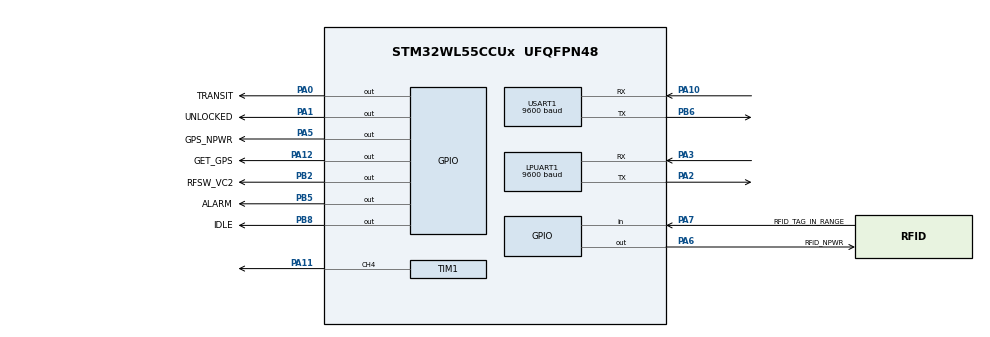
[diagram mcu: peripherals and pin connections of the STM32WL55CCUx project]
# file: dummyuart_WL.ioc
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ADC.ClockPrescaler=ADC_CLOCK_SYNC_PCLK_DIV4
ADC.NbrOfConversion=1
ADC.Overrun=ADC_OVR_DATA_OVERWRITTEN
ADC.SelectedChannel=ADC_CHANNEL_TEMPSENSOR|ADC_CHANNEL_VREFINT
LPUART1.BaudRate=9600
LPUART1.SwapParam=UART_ADVFEATURE_SWAP_ENABLE
Mcu.Family=STM32WL
Mcu.Name=STM32WL55CCUx
Mcu.Package=UFQFPN48
NVIC.LPUART1_IRQn=true\:0\:0\:false\:false\:true\:true\:true\:true
NVIC.PriorityGroup=NVIC_PRIORITYGROUP_4
NVIC.USART1_IRQn=true\:0\:0\:false\:false\:true\:true\:true\:true
PA0.GPIO_Label=TRANSIT
PA0.PinState=GPIO_PIN_SET
PA0.Signal=GPIO_Output
PA1.GPIO_Label=UNLOCKED
PA1.PinState=GPIO_PIN_SET
PA1.Signal=GPIO_Output
PA10.Mode=Asynchronous
PA10.Signal=USART1_RX
PA11.GPIO_Speed=GPIO_SPEED_FREQ_HIGH
PA11.Signal=S_TIM1_CH4
PA12.GPIO_Label=GET_GPS
PA12.PinState=GPIO_PIN_SET
PA12.Signal=GPIO_Output
PA13.Mode=Serial_Wire
PA13.Signal=DEBUG_JTMS-SWDIO
PA14.Mode=Serial_Wire
PA14.Signal=DEBUG_JTCK-SWCLK
PA2.Mode=Asynchronous
PA2.Signal=LPUART1_TX
PA3.Mode=Asynchronous
PA3.Signal=LPUART1_RX
PA5.GPIO_Label=GPS_NPWR
PA5.Signal=GPIO_Output
PA6.GPIO_Label=RFiD_NPWR
PA6.Signal=GPIO_Output
PA7.GPIO_Label=RFID_TAG_IN_RANGE
PA7.Signal=GPIO_Input
PB2.GPIO_Label=RFSW_VC2
PB2.Signal=GPIO_Output
PB4.Signal=DEBUG_JTRST
PB5.GPIO_Label=ALARM
PB5.PinState=GPIO_PIN_SET
PB5.Signal=GPIO_Output
PB6.Mode=Asynchronous
PB6.Signal=USART1_TX
PB8.GPIO_Label=IDLE
PB8.PinState=GPIO_PIN_SET
PB8.Signal=GPIO_Output
ProjectManager.HeapSize=0x200
ProjectManager.StackSize=0x400
ProjectManager.TargetToolchain=Makefile
RCC.AHBFreq_Value=48000000
RCC.APB1Freq_Value=48000000
RCC.APB1TimFreq_Value=48000000
RCC.APB2Freq_Value=48000000
RCC.APB2TimFreq_Value=48000000
RCC.APB3Freq_Value=48000000
RCC.CortexFreq_Value=48000000
RCC.HCLKFreq_Value=48000000
RCC.HSE_VALUE=8000000
RCC.HSI_VALUE=16000000
RCC.LPUART1CLockSelection=RCC_LPUART1CLKSOURCE_HSI
RCC.LSE_VALUE=32768
RCC.MSIClockRange=RCC_MSIRANGE_11
RCC.SYSCLKFreq_VALUE=48000000
RCC.USART1CLockSelection=RCC_USART1CLKSOURCE_HSI
RCC.VCOOutputFreq_Value=384000000
SH.S_TIM1_CH4.0=TIM1_CH4,PWM Generation4 CH4
TIM1.AutoReloadPreload=TIM_AUTORELOAD_PRELOAD_DISABLE
TIM1.Channel-PWM\ Generation4\ CH4=TIM_CHANNEL_4
TIM1.OCFastMode_PWM-PWM\ Generation4\ CH4=TIM_OCFAST_ENABLE
TIM1.Period=3
TIM1.Prescaler=2400
TIM1.Pulse-PWM\ Generation4\ CH4=2
TIM2.Period=5000000
TIM2.Prescaler=48000-1
USART1.AutoBaudRateEnableParam=UART_ADVFEATURE_AUTOBAUDRATE_DISABLE
USART1.BaudRate=9600
USART1.DataInvertParam=ADVFEATURE_DATAINV_DISABLE
USART1.FIFOMode=FIFOMODE_ENABLE
USART1.OneBitSampling=UART_ONE_BIT_SAMPLE_ENABLE
USART1.OverSampling=UART_OVERSAMPLING_8
USART1.RxPinLevelInvertParam=ADVFEATURE_RXINV_DISABLE
USART1.SwapParam=ADVFEATURE_SWAP_ENABLE
USART1.TxPinLevelInvertParam=ADVFEATURE_TXINV_DISABLE
USART1.VirtualMode-Asynchronous=VM_ASYNC
USART1.WordLength=WORDLENGTH_8B
VP_ADC_TempSens_Input.Mode=IN-TempSens
VP_ADC_Vref_Input.Mode=IN-Vrefint
VP_TIM1_VS_ClockSourceINT.Mode=Internal
VP_TIM2_VS_ClockSourceINT.Mode=Internal
board=custom

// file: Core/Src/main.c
/* USER CODE BEGIN Header */
/**
  ******************************************************************************
  * @file           : main.c
  * @brief          : Main program body
  ******************************************************************************
  * @attention
  *
  * Copyright (c) 2022 STMicroelectronics.
  * All rights reserved.
  *
  * This software is licensed under terms that can be found in the LICENSE file
  * in the root directory of this software component.
  * If no LICENSE file comes with this software, it is provided AS-IS.
  *
  ******************************************************************************
  */
/* USER CODE END Header */
#include "main.h"

 ADC_HandleTypeDef hadc;

UART_HandleTypeDef hlpuart1;
UART_HandleTypeDef huart1;

TIM_HandleTypeDef htim1;
TIM_HandleTypeDef htim2;

void SystemClock_Config(void);
static void MX_GPIO_Init(void);
static void MX_USART1_UART_Init(void);
static void MX_ADC_Init(void);
static void MX_LPUART1_UART_Init(void);
static void MX_TIM1_Init(void);
static void MX_TIM2_Init(void);

/* USER CODE BEGIN 0 */
char dummymsg[]={
		 "dummymessage \n\r"
 };
/* USER CODE END 0 */

int main(void)
{

  /* MCU Configuration--------------------------------------------------------*/

  /* Reset of all peripherals, Initializes the Flash interface and the Systick. */
  HAL_Init();

  /* Configure the system clock */
  SystemClock_Config();

  /* Initialize all configured peripherals */
  MX_GPIO_Init();
  MX_USART1_UART_Init();
  MX_ADC_Init();
  MX_LPUART1_UART_Init();
  MX_TIM1_Init();
  MX_TIM2_Init();

  /* Infinite loop */
  while (1)
  {

    /* USER CODE BEGIN 3 */
    for (int i=0; i<17; i++){
	  HAL_UART_Transmit(&huart1, &dummymsg[i], 1, 1000);
	  };
  }
  /* USER CODE END 3 */
}

void SystemClock_Config(void)
{
  RCC_OscInitTypeDef RCC_OscInitStruct = {0};
  RCC_ClkInitTypeDef RCC_ClkInitStruct = {0};

  /** Configure the main internal regulator output voltage
  */
  __HAL_PWR_VOLTAGESCALING_CONFIG(PWR_REGULATOR_VOLTAGE_SCALE1);

  /** Initializes the CPU, AHB and APB busses clocks
  */
  RCC_OscInitStruct.OscillatorType = RCC_OSCILLATORTYPE_HSI|RCC_OSCILLATORTYPE_MSI;
  RCC_OscInitStruct.HSIState = RCC_HSI_ON;
  RCC_OscInitStruct.MSIState = RCC_MSI_ON;
  RCC_OscInitStruct.HSICalibrationValue = RCC_HSICALIBRATION_DEFAULT;
  RCC_OscInitStruct.MSICalibrationValue = RCC_MSICALIBRATION_DEFAULT;
  RCC_OscInitStruct.MSIClockRange = RCC_MSIRANGE_11;
  RCC_OscInitStruct.PLL.PLLState = RCC_PLL_NONE;
  if (HAL_RCC_OscConfig(&RCC_OscInitStruct) != HAL_OK)
  {
    Error_Handler();
  }

  /** Configure the SYSCLKSource, HCLK, PCLK1 and PCLK2 clocks dividers
  */
  RCC_ClkInitStruct.ClockType = RCC_CLOCKTYPE_HCLK3|RCC_CLOCKTYPE_HCLK
                              |RCC_CLOCKTYPE_SYSCLK|RCC_CLOCKTYPE_PCLK1
                              |RCC_CLOCKTYPE_PCLK2;
  RCC_ClkInitStruct.SYSCLKSource = RCC_SYSCLKSOURCE_MSI;
  RCC_ClkInitStruct.AHBCLKDivider = RCC_SYSCLK_DIV1;
  RCC_ClkInitStruct.APB1CLKDivider = RCC_HCLK_DIV1;
  RCC_ClkInitStruct.APB2CLKDivider = RCC_HCLK_DIV1;
  RCC_ClkInitStruct.AHBCLK3Divider = RCC_SYSCLK_DIV1;

  if (HAL_RCC_ClockConfig(&RCC_ClkInitStruct, FLASH_LATENCY_2) != HAL_OK)
  {
    Error_Handler();
  }
}

static void MX_ADC_Init(void)
{

  /** Configure the global features of the ADC (Clock, Resolution, Data Alignment and number of conversion)
  */
  hadc.Instance = ADC;
  hadc.Init.ClockPrescaler = ADC_CLOCK_SYNC_PCLK_DIV4;
  hadc.Init.Resolution = ADC_RESOLUTION_12B;
  hadc.Init.DataAlign = ADC_DATAALIGN_RIGHT;
  hadc.Init.ScanConvMode = ADC_SCAN_DISABLE;
  hadc.Init.EOCSelection = ADC_EOC_SINGLE_CONV;
  hadc.Init.LowPowerAutoWait = DISABLE;
  hadc.Init.LowPowerAutoPowerOff = DISABLE;
  hadc.Init.ContinuousConvMode = DISABLE;
  hadc.Init.NbrOfConversion = 1;
  hadc.Init.DiscontinuousConvMode = DISABLE;
  hadc.Init.ExternalTrigConv = ADC_SOFTWARE_START;
  hadc.Init.ExternalTrigConvEdge = ADC_EXTERNALTRIGCONVEDGE_NONE;
  hadc.Init.DMAContinuousRequests = DISABLE;
  hadc.Init.Overrun = ADC_OVR_DATA_OVERWRITTEN;
  hadc.Init.SamplingTimeCommon1 = ADC_SAMPLETIME_1CYCLE_5;
  hadc.Init.SamplingTimeCommon2 = ADC_SAMPLETIME_1CYCLE_5;
  hadc.Init.OversamplingMode = DISABLE;
  hadc.Init.TriggerFrequencyMode = ADC_TRIGGER_FREQ_HIGH;
  if (HAL_ADC_Init(&hadc) != HAL_OK)
  {
    Error_Handler();
  }

}

static void MX_LPUART1_UART_Init(void)
{

  hlpuart1.Instance = LPUART1;
  hlpuart1.Init.BaudRate = 9600;
  hlpuart1.Init.WordLength = UART_WORDLENGTH_8B;
  hlpuart1.Init.StopBits = UART_STOPBITS_1;
  hlpuart1.Init.Parity = UART_PARITY_NONE;
  hlpuart1.Init.Mode = UART_MODE_TX_RX;
  hlpuart1.Init.HwFlowCtl = UART_HWCONTROL_NONE;
  hlpuart1.Init.OneBitSampling = UART_ONE_BIT_SAMPLE_DISABLE;
  hlpuart1.Init.ClockPrescaler = UART_PRESCALER_DIV1;
  hlpuart1.AdvancedInit.AdvFeatureInit = UART_ADVFEATURE_SWAP_INIT;
  hlpuart1.AdvancedInit.Swap = UART_ADVFEATURE_SWAP_ENABLE;
  hlpuart1.FifoMode = UART_FIFOMODE_DISABLE;
  if (HAL_UART_Init(&hlpuart1) != HAL_OK)
  {
    Error_Handler();
  }
  if (HAL_UARTEx_SetTxFifoThreshold(&hlpuart1, UART_TXFIFO_THRESHOLD_1_8) != HAL_OK)
  {
    Error_Handler();
  }
  if (HAL_UARTEx_SetRxFifoThreshold(&hlpuart1, UART_RXFIFO_THRESHOLD_1_8) != HAL_OK)
  {
    Error_Handler();
  }
  if (HAL_UARTEx_DisableFifoMode(&hlpuart1) != HAL_OK)
  {
    Error_Handler();
  }

}

static void MX_USART1_UART_Init(void)
{

  huart1.Instance = USART1;
  huart1.Init.BaudRate = 9600;
  huart1.Init.WordLength = UART_WORDLENGTH_8B;
  huart1.Init.StopBits = UART_STOPBITS_1;
  huart1.Init.Parity = UART_PARITY_NONE;
  huart1.Init.Mode = UART_MODE_TX_RX;
  huart1.Init.HwFlowCtl = UART_HWCONTROL_NONE;
  huart1.Init.OverSampling = UART_OVERSAMPLING_8;
  huart1.Init.OneBitSampling = UART_ONE_BIT_SAMPLE_ENABLE;
  huart1.Init.ClockPrescaler = UART_PRESCALER_DIV1;
  huart1.AdvancedInit.AdvFeatureInit = UART_ADVFEATURE_SWAP_INIT;
  huart1.AdvancedInit.Swap = UART_ADVFEATURE_SWAP_ENABLE;
  if (HAL_UART_Init(&huart1) != HAL_OK)
  {
    Error_Handler();
  }
  if (HAL_UARTEx_SetTxFifoThreshold(&huart1, UART_TXFIFO_THRESHOLD_1_8) != HAL_OK)
  {
    Error_Handler();
  }
  if (HAL_UARTEx_SetRxFifoThreshold(&huart1, UART_RXFIFO_THRESHOLD_1_8) != HAL_OK)
  {
    Error_Handler();
  }
  if (HAL_UARTEx_EnableFifoMode(&huart1) != HAL_OK)
  {
    Error_Handler();
  }

}

static void MX_TIM1_Init(void)
{

  TIM_ClockConfigTypeDef sClockSourceConfig = {0};
  TIM_MasterConfigTypeDef sMasterConfig = {0};
  TIM_OC_InitTypeDef sConfigOC = {0};
  TIM_BreakDeadTimeConfigTypeDef sBreakDeadTimeConfig = {0};

  htim1.Instance = TIM1;
  htim1.Init.Prescaler = 2400;
  htim1.Init.CounterMode = TIM_COUNTERMODE_UP;
  htim1.Init.Period = 3;
  htim1.Init.ClockDivision = TIM_CLOCKDIVISION_DIV1;
  htim1.Init.RepetitionCounter = 0;
  htim1.Init.AutoReloadPreload = TIM_AUTORELOAD_PRELOAD_DISABLE;
  if (HAL_TIM_Base_Init(&htim1) != HAL_OK)
  {
    Error_Handler();
  }
  sClockSourceConfig.ClockSource = TIM_CLOCKSOURCE_INTERNAL;
  if (HAL_TIM_ConfigClockSource(&htim1, &sClockSourceConfig) != HAL_OK)
  {
    Error_Handler();
  }
  if (HAL_TIM_PWM_Init(&htim1) != HAL_OK)
  {
    Error_Handler();
  }
  sMasterConfig.MasterOutputTrigger = TIM_TRGO_RESET;
  sMasterConfig.MasterOutputTrigger2 = TIM_TRGO2_RESET;
  sMasterConfig.MasterSlaveMode = TIM_MASTERSLAVEMODE_DISABLE;
  if (HAL_TIMEx_MasterConfigSynchronization(&htim1, &sMasterConfig) != HAL_OK)
  {
    Error_Handler();
  }
  sConfigOC.OCMode = TIM_OCMODE_PWM1;
  sConfigOC.Pulse = 2;
  sConfigOC.OCPolarity = TIM_OCPOLARITY_HIGH;
  sConfigOC.OCFastMode = TIM_OCFAST_ENABLE;
  sConfigOC.OCIdleState = TIM_OCIDLESTATE_RESET;
  sConfigOC.OCNIdleState = TIM_OCNIDLESTATE_RESET;
  if (HAL_TIM_PWM_ConfigChannel(&htim1, &sConfigOC, TIM_CHANNEL_4) != HAL_OK)
  {
    Error_Handler();
  }
  sBreakDeadTimeConfig.OffStateRunMode = TIM_OSSR_DISABLE;
  sBreakDeadTimeConfig.OffStateIDLEMode = TIM_OSSI_DISABLE;
  sBreakDeadTimeConfig.LockLevel = TIM_LOCKLEVEL_OFF;
  sBreakDeadTimeConfig.DeadTime = 0;
  sBreakDeadTimeConfig.BreakState = TIM_BREAK_DISABLE;
  sBreakDeadTimeConfig.BreakPolarity = TIM_BREAKPOLARITY_HIGH;
  sBreakDeadTimeConfig.BreakFilter = 0;
  sBreakDeadTimeConfig.BreakAFMode = TIM_BREAK_AFMODE_INPUT;
  sBreakDeadTimeConfig.Break2State = TIM_BREAK2_DISABLE;
  sBreakDeadTimeConfig.Break2Polarity = TIM_BREAK2POLARITY_HIGH;
  sBreakDeadTimeConfig.Break2Filter = 0;
  sBreakDeadTimeConfig.Break2AFMode = TIM_BREAK_AFMODE_INPUT;
  sBreakDeadTimeConfig.AutomaticOutput = TIM_AUTOMATICOUTPUT_DISABLE;
  if (HAL_TIMEx_ConfigBreakDeadTime(&htim1, &sBreakDeadTimeConfig) != HAL_OK)
  {
    Error_Handler();
  }
  HAL_TIM_MspPostInit(&htim1);

}

static void MX_TIM2_Init(void)
{

  TIM_ClockConfigTypeDef sClockSourceConfig = {0};
  TIM_MasterConfigTypeDef sMasterConfig = {0};

  htim2.Instance = TIM2;
  htim2.Init.Prescaler = 48000-1;
  htim2.Init.CounterMode = TIM_COUNTERMODE_UP;
  htim2.Init.Period = 5000000;
  htim2.Init.ClockDivision = TIM_CLOCKDIVISION_DIV1;
  htim2.Init.AutoReloadPreload = TIM_AUTORELOAD_PRELOAD_DISABLE;
  if (HAL_TIM_Base_Init(&htim2) != HAL_OK)
  {
    Error_Handler();
  }
  sClockSourceConfig.ClockSource = TIM_CLOCKSOURCE_INTERNAL;
  if (HAL_TIM_ConfigClockSource(&htim2, &sClockSourceConfig) != HAL_OK)
  {
    Error_Handler();
  }
  sMasterConfig.MasterOutputTrigger = TIM_TRGO_RESET;
  sMasterConfig.MasterSlaveMode = TIM_MASTERSLAVEMODE_DISABLE;
  if (HAL_TIMEx_MasterConfigSynchronization(&htim2, &sMasterConfig) != HAL_OK)
  {
    Error_Handler();
  }

}

static void MX_GPIO_Init(void)
{
  GPIO_InitTypeDef GPIO_InitStruct = {0};

  /* GPIO Ports Clock Enable */
  __HAL_RCC_GPIOB_CLK_ENABLE();
  __HAL_RCC_GPIOA_CLK_ENABLE();

  /*Configure GPIO pin Output Level */
  HAL_GPIO_WritePin(GPIOB, ALARM_Pin|IDLE_Pin, GPIO_PIN_SET);

  /*Configure GPIO pin Output Level */
  HAL_GPIO_WritePin(GPIOA, TRANSIT_Pin|UNLOCKED_Pin|GET_GPS_Pin, GPIO_PIN_SET);

  /*Configure GPIO pin Output Level */
  HAL_GPIO_WritePin(GPIOA, GPS_NPWR_Pin|RFiD_NPWR_Pin, GPIO_PIN_RESET);

  /*Configure GPIO pin Output Level */
  HAL_GPIO_WritePin(RFSW_VC2_GPIO_Port, RFSW_VC2_Pin, GPIO_PIN_RESET);

  /*Configure GPIO pins : ALARM_Pin IDLE_Pin RFSW_VC2_Pin */
  GPIO_InitStruct.Pin = ALARM_Pin|IDLE_Pin|RFSW_VC2_Pin;
  GPIO_InitStruct.Mode = GPIO_MODE_OUTPUT_PP;
  GPIO_InitStruct.Pull = GPIO_NOPULL;
  GPIO_InitStruct.Speed = GPIO_SPEED_FREQ_LOW;
  HAL_GPIO_Init(GPIOB, &GPIO_InitStruct);

  /*Configure GPIO pins : TRANSIT_Pin UNLOCKED_Pin GPS_NPWR_Pin RFiD_NPWR_Pin
                           GET_GPS_Pin */
  GPIO_InitStruct.Pin = TRANSIT_Pin|UNLOCKED_Pin|GPS_NPWR_Pin|RFiD_NPWR_Pin
                          |GET_GPS_Pin;
  GPIO_InitStruct.Mode = GPIO_MODE_OUTPUT_PP;
  GPIO_InitStruct.Pull = GPIO_NOPULL;
  GPIO_InitStruct.Speed = GPIO_SPEED_FREQ_LOW;
  HAL_GPIO_Init(GPIOA, &GPIO_InitStruct);

  /*Configure GPIO pin : RFID_TAG_IN_RANGE_Pin */
  GPIO_InitStruct.Pin = RFID_TAG_IN_RANGE_Pin;
  GPIO_InitStruct.Mode = GPIO_MODE_INPUT;
  GPIO_InitStruct.Pull = GPIO_NOPULL;
  HAL_GPIO_Init(RFID_TAG_IN_RANGE_GPIO_Port, &GPIO_InitStruct);

}

void Error_Handler(void)
{
  __disable_irq();
  while (1)
  {
  }
}
